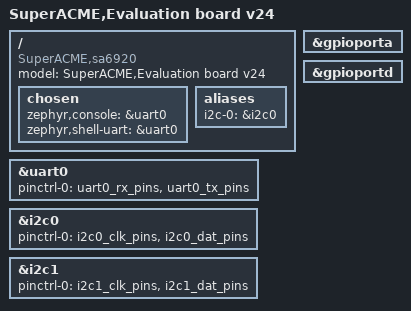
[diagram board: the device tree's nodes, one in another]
/*
 * Copyright (c) 2018-2025 SuperACME Electronics Corporation Holding Limited
 *
 * SPDX-License-Identifier: Apache-2.0
 */

/dts-v1/;

#include <acme/sa6920_star.dtsi>
#include <acme/sa6920_star_pinctrl.dtsi>
#include <zephyr/dt-bindings/input/input-event-codes.h>

/ {
	model = "SuperACME,Evaluation board v24";
	compatible = "SuperACME,sa6920";
	#address-cells = <1>;
	#size-cells = <1>;

	chosen {
		zephyr,console = &uart0;
		zephyr,shell-uart = &uart0;
		zephyr,shell-uart = &uart0;
	};

	aliases {
		i2c-0 = &i2c0;
	};
};

&uart0 {
	pinctrl-0 = <&uart0_rx_pins &uart0_tx_pins>;
	pinctrl-names = "default";
	status = "okay";
};

&i2c0 {
	pinctrl-0 = <&i2c0_clk_pins &i2c0_dat_pins>;
	pinctrl-names = "default";
	status = "okay";
};

&i2c1 {
	pinctrl-0 = <&i2c1_clk_pins &i2c1_dat_pins>;
	pinctrl-names = "default";
	status = "okay";
};

// &mmc0 {
// 	// pinctrl-0 = <&emmc_clk_pin &emmc_cmd_pin &emmc_dat0_pin &emmc_dat1_pin &emmc_dat2_pin &emmc_dat3_pin>;
// 	// pinctrl-names = "default";
// 	status = "okay";
// };

&gpioporta {
	status = "okay";
};

&gpioportd {
	status = "okay";
};
// &gpiob {
// 	status = "okay";
// };
// &gpioe {
// 	status = "okay";
// };
// &gpioc {
// 	status = "okay";
// };
// &gpiof {
// 	status = "okay";
// };
// &gpioh {
// 	status = "okay";
// };




